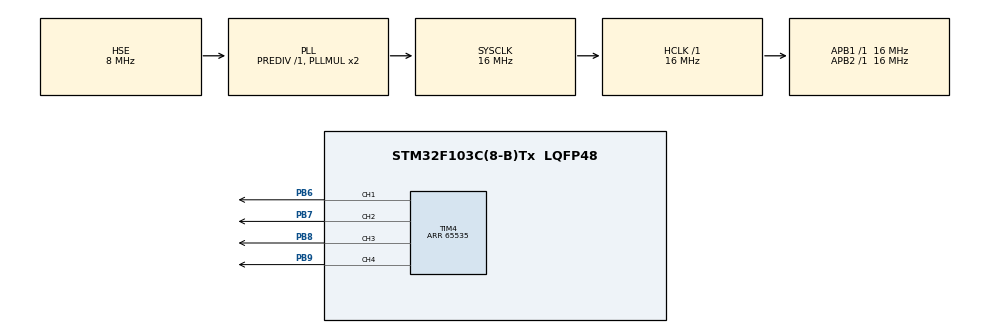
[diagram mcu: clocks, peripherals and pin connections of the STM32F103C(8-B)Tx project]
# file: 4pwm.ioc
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Mcu.Family=STM32F1
Mcu.Name=STM32F103C(8-B)Tx
Mcu.Package=LQFP48
NVIC.PriorityGroup=NVIC_PRIORITYGROUP_4
PA13.Signal=SYS_JTMS-SWDIO
PA14.Signal=SYS_JTCK-SWCLK
PB6.GPIO_Speed=GPIO_SPEED_FREQ_HIGH
PB6.Signal=S_TIM4_CH1
PB7.GPIO_Speed=GPIO_SPEED_FREQ_HIGH
PB7.Signal=S_TIM4_CH2
PB8.GPIO_Speed=GPIO_SPEED_FREQ_HIGH
PB8.Signal=S_TIM4_CH3
PB9.GPIO_Speed=GPIO_SPEED_FREQ_HIGH
PB9.Signal=S_TIM4_CH4
PD0-OSC_IN.Mode=HSE-External-Oscillator
PD0-OSC_IN.Signal=RCC_OSC_IN
PD1-OSC_OUT.Mode=HSE-External-Oscillator
PD1-OSC_OUT.Signal=RCC_OSC_OUT
ProjectManager.HeapSize=0x200
ProjectManager.StackSize=0x400
ProjectManager.TargetToolchain=MDK-ARM V5
RCC.AHBFreq_Value=16000000
RCC.APB1Freq_Value=16000000
RCC.APB1TimFreq_Value=16000000
RCC.APB2Freq_Value=16000000
RCC.APB2TimFreq_Value=16000000
RCC.HCLKFreq_Value=16000000
RCC.PLLSourceVirtual=RCC_PLLSOURCE_HSE
RCC.SYSCLKFreq_VALUE=16000000
RCC.SYSCLKSource=RCC_SYSCLKSOURCE_PLLCLK
RCC.USBFreq_Value=16000000
SH.S_TIM4_CH1.0=TIM4_CH1,PWM Generation1 CH1
SH.S_TIM4_CH2.0=TIM4_CH2,PWM Generation2 CH2
SH.S_TIM4_CH3.0=TIM4_CH3,PWM Generation3 CH3
SH.S_TIM4_CH4.0=TIM4_CH4,PWM Generation4 CH4
TIM4.Channel-PWM\ Generation1\ CH1=TIM_CHANNEL_1
TIM4.Channel-PWM\ Generation2\ CH2=TIM_CHANNEL_2
TIM4.Channel-PWM\ Generation3\ CH3=TIM_CHANNEL_3
TIM4.Channel-PWM\ Generation4\ CH4=TIM_CHANNEL_4
TIM4.Period=65535
TIM4.Pulse-PWM\ Generation1\ CH1=100
TIM4.Pulse-PWM\ Generation2\ CH2=200
TIM4.Pulse-PWM\ Generation3\ CH3=300
TIM4.Pulse-PWM\ Generation4\ CH4=500
board=4pwm

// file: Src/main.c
/**
  ******************************************************************************
  * File Name          : main.c
  * Description        : Main program body
  ******************************************************************************
  *
  * COPYRIGHT(c) 2017 STMicroelectronics
  *
  * Redistribution and use in source and binary forms, with or without modification,
  * are permitted provided that the following conditions are met:
  *   1. Redistributions of source code must retain the above copyright notice,
  *      this list of conditions and the following disclaimer.
  *   2. Redistributions in binary form must reproduce the above copyright notice,
  *      this list of conditions and the following disclaimer in the documentation
  *      and/or other materials provided with the distribution.
  *   3. Neither the name of STMicroelectronics nor the names of its contributors
  *      may be used to endorse or promote products derived from this software
  *      without specific prior written permission.
  *
  * THIS SOFTWARE IS PROVIDED BY THE COPYRIGHT HOLDERS AND CONTRIBUTORS "AS IS"
  * AND ANY EXPRESS OR IMPLIED WARRANTIES, INCLUDING, BUT NOT LIMITED TO, THE
  * IMPLIED WARRANTIES OF MERCHANTABILITY AND FITNESS FOR A PARTICULAR PURPOSE ARE
  * DISCLAIMED. IN NO EVENT SHALL THE COPYRIGHT HOLDER OR CONTRIBUTORS BE LIABLE
  * FOR ANY DIRECT, INDIRECT, INCIDENTAL, SPECIAL, EXEMPLARY, OR CONSEQUENTIAL
  * DAMAGES (INCLUDING, BUT NOT LIMITED TO, PROCUREMENT OF SUBSTITUTE GOODS OR
  * SERVICES; LOSS OF USE, DATA, OR PROFITS; OR BUSINESS INTERRUPTION) HOWEVER
  * CAUSED AND ON ANY THEORY OF LIABILITY, WHETHER IN CONTRACT, STRICT LIABILITY,
  * OR TORT (INCLUDING NEGLIGENCE OR OTHERWISE) ARISING IN ANY WAY OUT OF THE USE
  * OF THIS SOFTWARE, EVEN IF ADVISED OF THE POSSIBILITY OF SUCH DAMAGE.
  *
  ******************************************************************************
  */
#include "main.h"
#include "stm32f1xx_hal.h"

TIM_HandleTypeDef htim4;

/* USER CODE BEGIN PV */
/* Private variables ---------------------------------------------------------*/

/* USER CODE END PV */

void SystemClock_Config(void);
void Error_Handler(void);
static void MX_GPIO_Init(void);
static void MX_TIM4_Init(void);
void HAL_TIM_MspPostInit(TIM_HandleTypeDef *htim);

/* USER CODE BEGIN PFP */
/* Private function prototypes -----------------------------------------------*/

/* USER CODE END PFP */

int main(void)
{

  /* MCU Configuration----------------------------------------------------------*/

  /* Reset of all peripherals, Initializes the Flash interface and the Systick. */
  HAL_Init();

  /* Configure the system clock */
  SystemClock_Config();

  /* Initialize all configured peripherals */
  MX_GPIO_Init();
  MX_TIM4_Init();

  /* USER CODE BEGIN 2 */
HAL_TIM_PWM_Start(&htim4, TIM_CHANNEL_1);
HAL_TIM_PWM_Start(&htim4, TIM_CHANNEL_2);
HAL_TIM_PWM_Start(&htim4, TIM_CHANNEL_3);
HAL_TIM_PWM_Start(&htim4, TIM_CHANNEL_4);
  /* USER CODE END 2 */

  /* Infinite loop */
  while (1)
  {

  /* USER CODE BEGIN 3 */

		TIM4->CCR1 = 10000;

		/*for(int i = 0; i< 1000; i++)
{
  TIM4->CCR1 = i;
  for(int delay = 0; delay< 10000; delay++) __NOP();
}

for(int i = 1000; i>0; i--)
{
  TIM4->CCR1 = i;
  for(int delay = 0; delay< 10000; delay++) __NOP();
}*/
  }
  /* USER CODE END 3 */

}

/** System Clock Configuration
*/
void SystemClock_Config(void)
{

  RCC_OscInitTypeDef RCC_OscInitStruct;
  RCC_ClkInitTypeDef RCC_ClkInitStruct;

    /**Initializes the CPU, AHB and APB busses clocks
    */
  RCC_OscInitStruct.OscillatorType = RCC_OSCILLATORTYPE_HSE;
  RCC_OscInitStruct.HSEState = RCC_HSE_ON;
  RCC_OscInitStruct.HSEPredivValue = RCC_HSE_PREDIV_DIV1;
  RCC_OscInitStruct.HSIState = RCC_HSI_ON;
  RCC_OscInitStruct.PLL.PLLState = RCC_PLL_ON;
  RCC_OscInitStruct.PLL.PLLSource = RCC_PLLSOURCE_HSE;
  RCC_OscInitStruct.PLL.PLLMUL = RCC_PLL_MUL2;
  if (HAL_RCC_OscConfig(&RCC_OscInitStruct) != HAL_OK)
  {
    Error_Handler();
  }

    /**Initializes the CPU, AHB and APB busses clocks
    */
  RCC_ClkInitStruct.ClockType = RCC_CLOCKTYPE_HCLK|RCC_CLOCKTYPE_SYSCLK
                              |RCC_CLOCKTYPE_PCLK1|RCC_CLOCKTYPE_PCLK2;
  RCC_ClkInitStruct.SYSCLKSource = RCC_SYSCLKSOURCE_PLLCLK;
  RCC_ClkInitStruct.AHBCLKDivider = RCC_SYSCLK_DIV1;
  RCC_ClkInitStruct.APB1CLKDivider = RCC_HCLK_DIV1;
  RCC_ClkInitStruct.APB2CLKDivider = RCC_HCLK_DIV1;

  if (HAL_RCC_ClockConfig(&RCC_ClkInitStruct, FLASH_LATENCY_0) != HAL_OK)
  {
    Error_Handler();
  }

    /**Configure the Systick interrupt time
    */
  HAL_SYSTICK_Config(HAL_RCC_GetHCLKFreq()/1000);

    /**Configure the Systick
    */
  HAL_SYSTICK_CLKSourceConfig(SYSTICK_CLKSOURCE_HCLK);

  /* SysTick_IRQn interrupt configuration */
  HAL_NVIC_SetPriority(SysTick_IRQn, 0, 0);
}

/* TIM4 init function */
static void MX_TIM4_Init(void)
{

  TIM_MasterConfigTypeDef sMasterConfig;
  TIM_OC_InitTypeDef sConfigOC;

  htim4.Instance = TIM4;
  htim4.Init.Prescaler = 0;
  htim4.Init.CounterMode = TIM_COUNTERMODE_UP;
  htim4.Init.Period = 65535;
  htim4.Init.ClockDivision = TIM_CLOCKDIVISION_DIV1;
  if (HAL_TIM_PWM_Init(&htim4) != HAL_OK)
  {
    Error_Handler();
  }

  sMasterConfig.MasterOutputTrigger = TIM_TRGO_RESET;
  sMasterConfig.MasterSlaveMode = TIM_MASTERSLAVEMODE_DISABLE;
  if (HAL_TIMEx_MasterConfigSynchronization(&htim4, &sMasterConfig) != HAL_OK)
  {
    Error_Handler();
  }

  sConfigOC.OCMode = TIM_OCMODE_PWM1;
  sConfigOC.Pulse = 100;
  sConfigOC.OCPolarity = TIM_OCPOLARITY_HIGH;
  sConfigOC.OCFastMode = TIM_OCFAST_DISABLE;
  if (HAL_TIM_PWM_ConfigChannel(&htim4, &sConfigOC, TIM_CHANNEL_1) != HAL_OK)
  {
    Error_Handler();
  }

  sConfigOC.Pulse = 200;
  if (HAL_TIM_PWM_ConfigChannel(&htim4, &sConfigOC, TIM_CHANNEL_2) != HAL_OK)
  {
    Error_Handler();
  }

  sConfigOC.Pulse = 300;
  if (HAL_TIM_PWM_ConfigChannel(&htim4, &sConfigOC, TIM_CHANNEL_3) != HAL_OK)
  {
    Error_Handler();
  }

  sConfigOC.Pulse = 500;
  if (HAL_TIM_PWM_ConfigChannel(&htim4, &sConfigOC, TIM_CHANNEL_4) != HAL_OK)
  {
    Error_Handler();
  }

  HAL_TIM_MspPostInit(&htim4);

}

/** Configure pins as
        * Analog
        * Input
        * Output
        * EVENT_OUT
        * EXTI
*/
static void MX_GPIO_Init(void)
{

  /* GPIO Ports Clock Enable */
  __HAL_RCC_GPIOD_CLK_ENABLE();
  __HAL_RCC_GPIOA_CLK_ENABLE();
  __HAL_RCC_GPIOB_CLK_ENABLE();

}

void Error_Handler(void)
{
  while(1)
  {
  }
}

/************************ (C) COPYRIGHT STMicroelectronics *****END OF FILE****/
